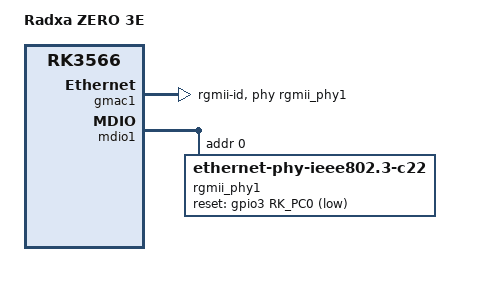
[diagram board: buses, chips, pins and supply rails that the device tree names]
// SPDX-License-Identifier: (GPL-2.0+ OR MIT)

/dts-v1/;

#include "rk3566-radxa-zero3.dtsi"

/ {
	model = "Radxa ZERO 3E";
	compatible = "radxa,zero-3e", "rockchip,rk3566";

	aliases {
		ethernet0 = &gmac1;
	};
};

&gmac1 {
	assigned-clocks = <&cru SCLK_GMAC1_RX_TX>, <&cru SCLK_GMAC1>;
	assigned-clock-parents = <&cru SCLK_GMAC1_RGMII_SPEED>;
	assigned-clock-rates = <0>, <125000000>;
	clock_in_out = "output";
	phy-handle = <&rgmii_phy1>;
	phy-mode = "rgmii-id";
	pinctrl-names = "default";
	pinctrl-0 = <&gmac1m1_miim
		     &gmac1m1_tx_bus2
		     &gmac1m1_rx_bus2
		     &gmac1m1_rgmii_clk
		     &gmac1m1_rgmii_bus
		     &gmac1m1_clkinout>;
	status = "okay";
};

&mdio1 {
	rgmii_phy1: ethernet-phy@0 {
		compatible = "ethernet-phy-ieee802.3-c22";
		reg = <0x0>;
		reset-assert-us = <20000>;
		reset-deassert-us = <100000>;
		reset-gpios = <&gpio3 RK_PC0 GPIO_ACTIVE_LOW>;
	};
};
